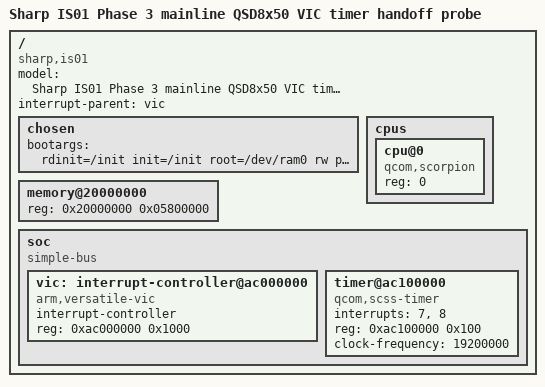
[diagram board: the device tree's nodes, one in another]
/dts-v1/;

/ {
	model = "Sharp IS01 Phase 3 mainline QSD8x50 VIC timer handoff probe";
	compatible = "sharp,is01", "qcom,qsd8x50";
	#address-cells = <1>;
	#size-cells = <1>;
	interrupt-parent = <&vic>;

	chosen {
		bootargs = "rdinit=/init init=/init root=/dev/ram0 rw panic=20 ignore_loglevel";
	};

	memory@20000000 {
		device_type = "memory";
		reg = <0x20000000 0x05800000>;
	};

	cpus {
		#address-cells = <1>;
		#size-cells = <0>;

		cpu@0 {
			device_type = "cpu";
			compatible = "qcom,scorpion";
			reg = <0>;
		};
	};

	soc {
		compatible = "simple-bus";
		#address-cells = <1>;
		#size-cells = <1>;
		ranges;

		vic: interrupt-controller@ac000000 {
			compatible = "arm,versatile-vic";
			interrupt-controller;
			#interrupt-cells = <1>;
			reg = <0xac000000 0x1000>;
		};

		timer@ac100000 {
			compatible = "qcom,scss-timer", "qcom,msm-timer";
			interrupts = <7>, <8>;
			reg = <0xac100000 0x100>;
			clock-frequency = <19200000>;
		};
	};
};
